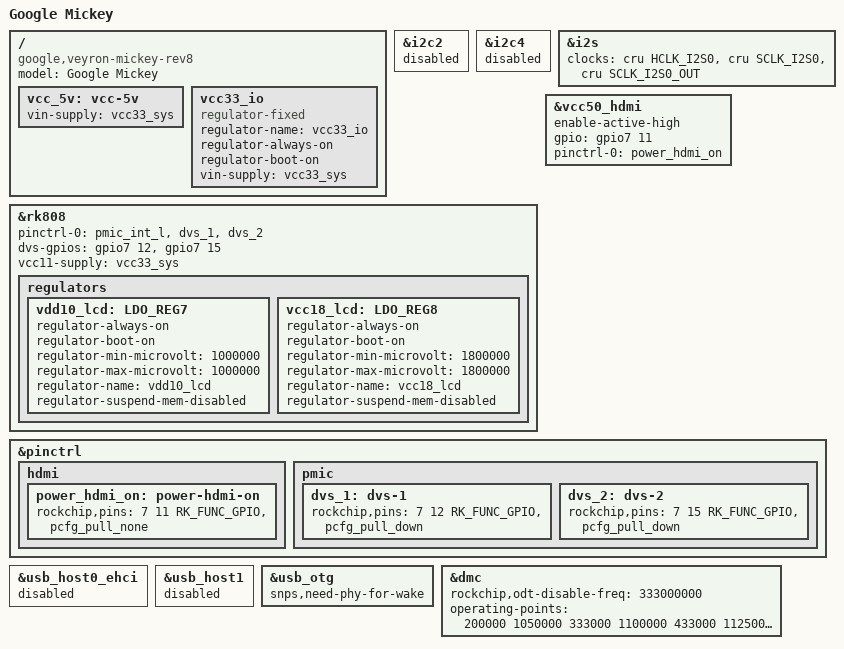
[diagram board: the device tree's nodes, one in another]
/*
 * Google Veyron Mickey Rev 0 board device tree source
 *
 * Copyright 2015 Google, Inc
 *
 * This program is free software; you can redistribute it and/or modify
 * it under the terms of the GNU General Public License version 2 as
 * published by the Free Software Foundation.
 */

/dts-v1/;
#include "rk3288-veyron.dtsi"
#include "rk3288-veyron-lpddr.dtsi"

#include "rk3288-mickey-thermal.dtsi"

/ {
	model = "Google Mickey";
	compatible = "google,veyron-mickey-rev8", "google,veyron-mickey-rev7",
		     "google,veyron-mickey-rev6", "google,veyron-mickey-rev5",
		     "google,veyron-mickey-rev4", "google,veyron-mickey-rev3",
		     "google,veyron-mickey-rev2", "google,veyron-mickey-rev1",
		     "google,veyron-mickey-rev0", "google,veyron-mickey",
	             "google,veyron", "rockchip,rk3288";

	vcc_5v: vcc-5v {
		vin-supply = <&vcc33_sys>;
	};

	vcc33_io: vcc33_io {
		compatible = "regulator-fixed";
		regulator-name = "vcc33_io";
		regulator-always-on;
		regulator-boot-on;
		vin-supply = <&vcc33_sys>;
	};
};

&i2c2 {
	status = "disabled";
};

&i2c4 {
	status = "disabled";
};

&i2s {
	status = "okay";
	clock-names = "i2s_hclk", "i2s_clk", "i2s_clk_out";
	clocks = <&cru HCLK_I2S0>, <&cru SCLK_I2S0>, <&cru SCLK_I2S0_OUT>;
};

&rk808 {
	pinctrl-names = "default";
	pinctrl-0 = <&pmic_int_l &dvs_1 &dvs_2>;
	dvs-gpios = <&gpio7 12 GPIO_ACTIVE_HIGH>,
		    <&gpio7 15 GPIO_ACTIVE_HIGH>;

	/delete-property/ vcc6-supply;
	/delete-property/ vcc12-supply;

	vcc11-supply = <&vcc33_sys>;

	regulators {
		/* vcc33_io is sourced directly from vcc33_sys */
		/delete-node/ LDO_REG1;
		/delete-node/ LDO_REG7;

		/* This is not a pwren anymore, but the real power supply */
		vdd10_lcd: LDO_REG7 {
			regulator-always-on;
			regulator-boot-on;
			regulator-min-microvolt = <1000000>;
			regulator-max-microvolt = <1000000>;
			regulator-name = "vdd10_lcd";
			regulator-suspend-mem-disabled;
		};

		vcc18_lcd: LDO_REG8 {
			regulator-always-on;
			regulator-boot-on;
			regulator-min-microvolt = <1800000>;
			regulator-max-microvolt = <1800000>;
			regulator-name = "vcc18_lcd";
			regulator-suspend-mem-disabled;
		};
	};
};

&vcc50_hdmi {
	enable-active-high;
	gpio = <&gpio7 11 GPIO_ACTIVE_HIGH>;
	pinctrl-names = "default";
	pinctrl-0 = <&power_hdmi_on>;
};

&pinctrl {
	hdmi {
		power_hdmi_on: power-hdmi-on {
			rockchip,pins = <7 11 RK_FUNC_GPIO &pcfg_pull_none>;
		};
	};

	pmic {
		dvs_1: dvs-1 {
			rockchip,pins = <7 12 RK_FUNC_GPIO &pcfg_pull_down>;
		};

		dvs_2: dvs-2 {
			rockchip,pins = <7 15 RK_FUNC_GPIO &pcfg_pull_down>;
		};
	};
};

&usb_host0_ehci {
	status = "disabled";
};

&usb_host1 {
	status = "disabled";
};

&usb_otg {
	/* We'll allow OTG port to wakeup on mickey; see main veyron dtsi */
	snps,need-phy-for-wake;
};

&dmc {
	rockchip,odt-disable-freq = <333000000>;
	operating-points = <
		/* KHz    uV */
		200000 1050000
		333000 1100000
		433000 1125000
		533000 1150000
	>;
};
